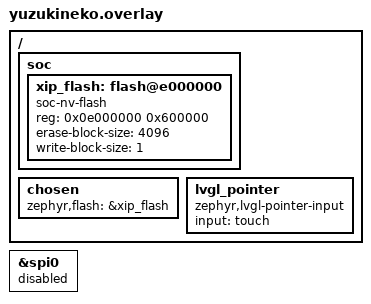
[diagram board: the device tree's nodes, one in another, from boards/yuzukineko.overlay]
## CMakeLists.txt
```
# SPDX-License-Identifier: Apache-2.0

cmake_minimum_required(VERSION 3.20.0)
# the WiFi driver sits next to this application
list(APPEND ZEPHYR_EXTRA_MODULES ${CMAKE_CURRENT_SOURCE_DIR}/../aic8800)

find_package(Zephyr REQUIRED HINTS $ENV{ZEPHYR_BASE})
project(bilibili_tv)

# math.h for the TrueType rasteriser of LVGL (the minimal C library has none); the functions are in libm
zephyr_include_directories(shim)
zephyr_link_libraries(-lm)
target_compile_options(modules__lvgl PRIVATE -include ${CMAKE_CURRENT_SOURCE_DIR}/shim/stbtt_cfg.h)
# TinyTTF releases a kerning cache entry into the glyph cache (lv_tiny_ttf.c, ttf_get_glyph_pair_kerning_width),
# which corrupts both caches: glyphs came out overlapped and with wrong advances. Without a kerning cache
# the width is computed directly (its Kconfig symbol is a bool, it cannot be set to 0 there)
target_compile_definitions(modules__lvgl PRIVATE LV_TINY_TTF_CACHE_KERNING_CNT=0)

# sources include each other by their path below src ("net/http.h")
target_include_directories(app PRIVATE src)
# LVGL includes lv_rvv.h from its blend sources
zephyr_include_directories(src/gfx)

# the video player (MP4 demultiplexer, H.264 and AAC decoders, display and sound) is a copy of the one of
# the NekoBox application, changed for a file that grows while it is played
file(GLOB PLAYER_SRC src/player/*.c)
target_sources(app PRIVATE ${PLAYER_SRC})

file(GLOB CORE_SRC src/core/*.c)
target_sources(app PRIVATE src/main.c ${CORE_SRC})
# network and file transfer, the Bilibili interface, the screens
file(GLOB NET_SRC src/net/*.c)
file(GLOB API_SRC src/api/*.c)
file(GLOB UI_SRC src/ui/*.c)
target_sources(app PRIVATE ${NET_SRC} ${API_SRC} ${UI_SRC})
target_sources_ifdef(CONFIG_BILI_SELFTEST app PRIVATE src/debug/selftest.c)
if(CONFIG_BILI_SELFTEST OR CONFIG_BILI_SCROLL_LOG)
  target_sources(app PRIVATE src/debug/profile.c)
endif()

# the Chinese font (tools/make_font.py) is part of the image
generate_inc_file_for_target(app src/ui/fonts/NotoSansSC-subset.ttf ${CMAKE_CURRENT_BINARY_DIR}/font.inc)
target_include_directories(app PRIVATE ${CMAKE_CURRENT_BINARY_DIR})

if(CONFIG_BILI_HOT_RAM)
  # only the files that run for every picture; relocating a whole library keeps every function
  set(V ${ZEPHYR_BASE}/drivers/vdec/sunxi)
  zephyr_code_relocate(FILES
    ${V}/vdec_sunxi.c ${V}/ve_hw.c ${V}/ve_mem.c ${V}/ve_pool.c ${V}/ve_session.c ${V}/ve_stream.c
    ${V}/ve_h264.c ${V}/ve_h264_parse.c ${V}/ve_h264_dpb.c ${V}/ve_h264_hw.c
    LOCATION RAM_TEXT)
  zephyr_code_relocate(LIBRARY opencore_aac LOCATION RAM_TEXT)
endif()

if(CONFIG_BILI_UI_RAM)
  # code of the interface runs from RAM: the flash window is not cached for data and every I-cache
  # miss of the drawing loops costs a flash read, which shows when the lists scroll
  zephyr_code_relocate(LIBRARY modules__lvgl LOCATION RAM_TEXT)
  zephyr_code_relocate(FILES ${UI_SRC} LOCATION RAM_TEXT)
endif()

target_sources_ifdef(CONFIG_BILI_CRUMBS app PRIVATE src/debug/crumbs.c)

if(CONFIG_BILI_GFX_RVV)
  target_sources(app PRIVATE src/gfx/lv_rvv.c)
  # only these files use vector instructions; the rest of the image is built as usual
  set_source_files_properties(src/gfx/lv_rvv.c PROPERTIES COMPILE_OPTIONS
    "-march=rv32imafdcv_zicsr_zifencei_xtheadcmo_xtheadba_xtheadbb_xtheadbs_xtheadcondmov_xtheadmemidx_xtheadmempair")
  if(CONFIG_BILI_HOT_RAM)
    zephyr_code_relocate(FILES ${CMAKE_CURRENT_SOURCE_DIR}/src/gfx/lv_rvv.c LOCATION RAM_TEXT)
  endif()
endif()

target_sources_ifdef(CONFIG_BILI_G2D_BENCH app PRIVATE src/debug/g2dbench.c)

target_sources_ifdef(CONFIG_BILI_SCROLL_SHIFT app PRIVATE src/gfx/shift.c)
```

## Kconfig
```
# SPDX-License-Identifier: Apache-2.0

mainmenu "Bilibili TV"

config BILI_WIFI_SSID
	string "Wi-Fi network to join at start"
	default ""

config BILI_WIFI_PSK
	string "Wi-Fi passphrase (empty: open network)"
	default ""

config BILI_PROXY
	string "HTTP proxy (host:port) for every request, empty for a direct connection"
	default ""
	help
	  With a proxy the plain requests are sent with the full address and the https ones through a
	  CONNECT tunnel, on which the TLS handshake is done by the application (the certificate of the
	  server is not checked). It can be changed at run time with  bili proxy <host:port|off>.

config BILI_FEED_COUNT
	int "Videos asked from the recommendation feed"
	default 12
	range 1 30

config BILI_CACHE_DIR
	string "Directory on the card where videos are stored while they play"
	default "/SD:/bilibili"

config NEKOBOX_VIDEO_STREAM_KB
	int "Stream buffer of the video decoder in KiB"
	default 256
	help
	  The videos here are 360P at under 1 Mbit/s: a quarter of a MiB holds seconds of them, and the
	  memory that the player of NekoBox would keep for 1 MiB goes to the decoder's pictures.

config BILI_HOT_RAM
	bool "Run the video decoder driver and the AAC decoder from RAM"
	default y
	depends on XIP
	select CODE_DATA_RELOCATION
	help
	  In an XIP image every instruction that is not in the cache comes from the flash window.
	  The decoder driver and the AAC decoder run on every picture, so their text is copied to RAM
	  at boot; the rest (kernel, other drivers, LVGL, the file system) stays in the flash.

config BILI_DM_MAX_ITEMS
	int "Most comments (danmaku) kept of a video"
	default 4000
	range 100 20000

config BILI_DM_POOL_KB
	int "Memory for the text of the comments (KiB)"
	default 160
	range 16 2048

config BILI_DM_ACTIVE
	int "Comments on the screen at the same time"
	default 20
	range 4 60
	help
	  Each one is a label that LVGL has to redraw while it moves: this is what the player pays for the
	  comments. A comment that finds no free label or lane within a second and a half is dropped.

config BILI_STREAM
	bool "Play while the file downloads"
	default y
	help
	  Off: the whole file is downloaded first (a long wait for a big video).

config BILI_UI_RAM
	bool "Run LVGL and the interface code from RAM"
	depends on XIP
	select CODE_DATA_RELOCATION
	default y

config BILI_PREBUFFER_SEC
	int "Seconds of video to download before playing starts"
	default 6
	range 0 30
	help
	  Avoids stalls in the first seconds while the connection speeds up. 0: start at once.

config BILI_PREBUFFER_TIMEOUT_SEC
	int "Longest wait for the prebuffer, in seconds"
	default 20
	range 1 120

config BILI_DM_FETCH
	bool "Fetch the comments of a video before it plays"
	default y

config BILI_DM_SHIFT
	bool "Move the picture of the scrolling comments with the 2D accelerator"
	default y
	help
	  The scrolling comments all move with the same speed. The picture of their lanes is moved to
	  the left by the accelerator and only the columns that come in at the right are drawn, instead of
	  drawing every label again at its new place.

config BILI_DM_VSYNC
	bool "Wait for the vertical blank before the scrolling comments are moved"
	depends on BILI_DM_SHIFT
	default n
	help
	  Without the wait the interface does not stand still for about 11 ms per round; the move of a
	  few pixels may show a seam for one frame.

config BILI_DM_DEFAULT
	bool "Show the comments when a video starts"
	default y

config BILI_SELFTEST
	bool "Scroll the list, search, play videos and check the memory by itself, ending with PASS or FAIL"
	select THREAD_MONITOR
	select THREAD_NAME
	select THREAD_RUNTIME_STATS
	select SYS_HEAP_RUNTIME_STATS
	help
	  Needs the network and the card. See src/debug/selftest.c.

config BILI_SELFTEST_ROUNDS
	int "Times the list is scrolled to its end and back"
	depends on BILI_SELFTEST
	default 3

config BILI_SELFTEST_PLAYS
	int "Videos that are played"
	depends on BILI_SELFTEST
	default 3

config BILI_HEARTBEAT
	bool "Print a line with the state of the cover cache every 10 s"
	default y

config BILI_COVER_THREADS
	int "Threads that fetch cover pictures at the same time"
	default 3
	range 1 6

config BILI_COVER_CACHE
	int "Cover pictures kept in memory (62 KiB each)"
	default 24
	range 8 60

config BILI_CDN_HTTPS
	bool "Fetch the video over TLS too"
	default y
	help
	  Every connection to a Bilibili server is encrypted: the API always, the video with this option
	  (an address that comes as http:// is changed to https://). The video servers also answer on
	  plain HTTP, which costs the CPU nothing.

config BILI_COVER_HTTPS
	bool "Fetch the covers and the pictures of the users over TLS"
	default y
	help
	  The picture servers also answer on plain HTTP. With TLS every picture costs a handshake.

config BILI_TLS_VERIFY
	bool "Check the certificate of the API server"
	help
	  Needs the root certificate to be registered (not done yet): with this off the connection is
	  encrypted but the server is not authenticated.

source "Kconfig.zephyr"

config BILI_CPU_MHZ
	int "CPU clock in MHz, 0 keeps what the boot stub set up (600)"
	default 600
	help
	  The CPU PLL is raised in steps of 72 MHz and the memory is checked after each step. The
	  voltage is not changed.

config BILI_CRUMBS
	bool "Keep the last context switches in memory and reset by a watchdog when the system stops"
	default y
	select WATCHDOG
	select WDT_SUNXI
	select THREAD_NAME

config BILI_CRUMBS_TIMEOUT_MS
	int "Watchdog time out in ms"
	depends on BILI_CRUMBS
	default 8000

config BILI_CRUMBS_TEST_S
	int "Stop the system after this many seconds (0: never), to try the recorder"
	depends on BILI_CRUMBS
	default 0

config BILI_SELFTEST_PLAY_POPULAR
	bool "Play the videos of the popular list (default: the recommended ones)"
	depends on BILI_SELFTEST

config BILI_SELFTEST_PLAY_SECONDS
	int "Seconds each video is played"
	depends on BILI_SELFTEST
	default 12
	range 12 600

config BILI_DM_LOG
	bool "Print how long the interface rounds take while comments are shown"
	default n

config BILI_SELFTEST_WIFI_ONLY
	bool "Only try the connection (leave, join again, wrong password, forget and save again)"
	depends on BILI_SELFTEST

config BILI_SELFTEST_PLAY_ONLY
	bool "Self test: load the list and play videos one after another, nothing else"
	depends on BILI_SELFTEST
	default n

config BILI_GFX_RVV
	bool "Vector code for the blends of LVGL"
	default y
	select SUN252I_F101_RVV
	help
	  The blends are compared with the C code of LVGL at start and the vector code is switched off
	  when they differ.

config BILI_G2D_BENCH
	bool "Measure the 2D accelerator against the processor at start"
	select G2D
	select G2D_SUNXI
	default n

config BILI_SCROLL_LOG
	bool "Print the refreshes that take longer than 40 ms"
	select THREAD_MONITOR
	select THREAD_NAME
	select THREAD_RUNTIME_STATS
	default n

config BILI_SCROLL_SHIFT
	bool "Scroll a list by moving the picture with the 2D accelerator and drawing only the new rows"
	select G2D
	select G2D_SUNXI
	default y

config BILI_COVER_G2D
	bool "Convert the pictures of the covers with the 2D accelerator"
	select G2D
	select G2D_SUNXI
	default y
```

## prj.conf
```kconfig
# the whole image runs in place from the flash window of the SPIF controller (boards/yuzukineko.overlay)
CONFIG_XIP=y

CONFIG_SDHC=y
CONFIG_DISK_ACCESS=y
CONFIG_DISK_DRIVER_SDMMC=y
CONFIG_FILE_SYSTEM=y
CONFIG_FAT_FILESYSTEM_ELM=y
CONFIG_FS_FATFS_EXFAT=y
CONFIG_FS_FATFS_LFN=y
CONFIG_FS_FATFS_LFN_MODE_STACK=y
# the audio and the video thread read the same card, and the downloader writes to it
CONFIG_FS_FATFS_REENTRANT=y
CONFIG_FS_FATFS_MKFS=n
CONFIG_FS_FATFS_MOUNT_MKFS=n

CONFIG_LOG=y
CONFIG_LOG_PRINTK=n
CONFIG_PRINTK=y
CONFIG_SHELL=n
# stack use of every thread: kernel stacks; an overflow is caught by the sentinel
CONFIG_THREAD_STACK_INFO=y
CONFIG_INIT_STACKS=y
CONFIG_STACK_SENTINEL=y
CONFIG_DEVMEM_SHELL=n
CONFIG_MAIN_STACK_SIZE=16384
CONFIG_COMMON_LIBC_MALLOC_ARENA_SIZE=-1
CONFIG_HEAP_MEM_POOL_SIZE=131072
CONFIG_MAIN_THREAD_PRIORITY=6
CONFIG_THREAD_NAME=y
CONFIG_SPEED_OPTIMIZATIONS=y

# drivers the application does not use
# CONFIG_G2D is selected by BILI_G2D_BENCH
CONFIG_ADC=n
CONFIG_SPI=n
CONFIG_MIPI_DBI=n
CONFIG_WDT_SUNXI=y
CONFIG_GPIO=y
CONFIG_FPU=y
CONFIG_FPU_SHARING=y

# the player. The budget of the video decoder is what is left of the 16 MB after the image (the font, the
# frame buffer and the WiFi firmware are in it): the stream buffer (NEKOBOX_VIDEO_STREAM_KB, 256) and the
# rest for the pictures, 4300 KiB is 11 pictures of 640x360. With 3200 only 6 were made, the decoder
# (references, the picture in work, the converted one, the one on the screen) found none free and stood
# still after the first picture; with 9 there were pictures late all the time. 12288, the default, does
# not fit the memory.
CONFIG_VDEC_SUNXI_MAX_MEMORY_KB=8192
CONFIG_MP4_DEMUX=y
CONFIG_VDEC=y
CONFIG_I2S=y
CONFIG_AUDIO=y
CONFIG_AUDIO_CODEC=y
CONFIG_DMA=y
CONFIG_OPENCORE_AAC=y

# the user interface: LVGL on the ARGB frame buffer plane, over the video plane
CONFIG_DISPLAY=y
CONFIG_DISPLAY_SUNXI_ARGB8888=y
CONFIG_LVGL=y
CONFIG_LV_COLOR_DEPTH_32=y
CONFIG_LV_Z_MEM_POOL_SIZE=720896
CONFIG_LV_Z_VDB_SIZE=10
CONFIG_LV_Z_SHELL=n
CONFIG_LV_USE_LABEL=y
CONFIG_LV_USE_BUTTON=y
CONFIG_LV_USE_BAR=y
# bili shot: the screen as a picture over the serial line (there is no camera on the bench)
CONFIG_LV_USE_SNAPSHOT=y
# a character that the font does not have is left blank, not drawn as a box
CONFIG_LV_USE_FONT_PLACEHOLDER=n
CONFIG_LV_USE_KEYBOARD=y
CONFIG_LV_USE_TEXTAREA=y
CONFIG_LV_USE_QRCODE=y
CONFIG_LV_USE_IME_PINYIN=y
CONFIG_LV_IME_PINYIN_USE_DEFAULT_DICT=n
CONFIG_LV_IME_PINYIN_CAND_TEXT_NUM=10
CONFIG_LV_FONT_MONTSERRAT_16=y
CONFIG_LV_FONT_MONTSERRAT_20=y
CONFIG_LV_FONT_MONTSERRAT_28=y
# the Chinese font is in the image
CONFIG_LV_USE_TINY_TTF=y
# software JPEG decoder for the covers that the video engine refuses
CONFIG_LV_USE_TJPGD=y

# Wi-Fi (AIC8800 on SMHC2)
CONFIG_AIC8800=y
# the driver used at most 310 KiB of its pool in the tests
CONFIG_AIC8800_MEM_POOL_KB=640
CONFIG_TEST_RANDOM_GENERATOR=y
CONFIG_SYSTEM_WORKQUEUE_STACK_SIZE=4096
CONFIG_NET_MGMT_EVENT_STACK_SIZE=3072
CONFIG_NET_RX_STACK_SIZE=3072
CONFIG_NET_TX_STACK_SIZE=2048
CONFIG_NET_TCP_WORKQ_STACK_SIZE=3072
CONFIG_NET_IPV6=n
CONFIG_NET_UDP=y
CONFIG_NET_TCP=y
CONFIG_NET_DHCPV4=y
CONFIG_NET_DHCPV4_OPTION_DNS_ADDRESS=y
CONFIG_NET_SOCKETS=y
# the receive window must fit in the buffers: a burst of a peer with a bigger window than the pool was
# dropped and every loss cost a retransmission time out (a 10 KB cover took 2 s)
CONFIG_NET_BUF_DATA_SIZE=512
CONFIG_NET_BUF_RX_COUNT=192
CONFIG_NET_BUF_TX_COUNT=96
CONFIG_NET_PKT_RX_COUNT=64
CONFIG_NET_PKT_TX_COUNT=48
CONFIG_NET_TCP_MAX_RECV_WINDOW_SIZE=16384
# every request opens a connection of its own; a closed one is held for the time wait: with the cover
# threads the table of 16 ran out ("Not enough connection contexts", connect() answered ENOENT)
CONFIG_NET_MAX_CONN=48
CONFIG_NET_MAX_CONTEXTS=48
CONFIG_NET_TCP_TIME_WAIT_DELAY=500
CONFIG_NET_CONTEXT_RCVTIMEO=y
CONFIG_NET_CONTEXT_SNDTIMEO=y
CONFIG_DNS_RESOLVER=y
CONFIG_DNS_RESOLVER_MAX_SERVERS=2
# the answer of api.bilibili.com has six addresses; a longer answer than this makes getaddrinfo() fail
CONFIG_DNS_RESOLVER_AI_MAX_ENTRIES=8
# the cover threads, the worker and the downloads resolve names at the same time; the default is one query at a time and the others get EAGAIN
CONFIG_DNS_NUM_CONCUR_QUERIES=6

# TLS for the API (the answers are a few KiB, but a handshake needs the records of the server)
CONFIG_NET_SOCKETS_SOCKOPT_TLS=y
CONFIG_MBEDTLS=y
CONFIG_MBEDTLS_BUILTIN=y
CONFIG_MBEDTLS_ENABLE_HEAP=y
# every connection to a Bilibili server is encrypted: the cover threads, the worker and the download
# can each have one open at the same time (about 55 KiB of the mbed TLS heap each)
CONFIG_NET_SOCKETS_TLS_MAX_CONTEXTS=4
CONFIG_MBEDTLS_HEAP_SIZE=262144
CONFIG_MBEDTLS_SSL_IN_CONTENT_LEN=16384
CONFIG_MBEDTLS_SSL_OUT_CONTENT_LEN=16384
CONFIG_PSA_CRYPTO=y
CONFIG_MBEDTLS_SSL_PROTO_TLS1_2=y
CONFIG_MBEDTLS_SSL_SERVER_NAME_INDICATION=y
CONFIG_MBEDTLS_X509_CRT_PARSE_C=y
CONFIG_PSA_WANT_ALG_ECDH=y
CONFIG_PSA_WANT_KEY_TYPE_ECC_KEY_PAIR_GENERATE=y
CONFIG_PSA_WANT_KEY_TYPE_ECC_KEY_PAIR_IMPORT=y
CONFIG_PSA_WANT_KEY_TYPE_RSA_KEY_PAIR_IMPORT=y
CONFIG_PSA_WANT_KEY_TYPE_RSA_PUBLIC_KEY=y
CONFIG_PSA_WANT_ALG_RSA_PKCS1V15_SIGN=y
CONFIG_PSA_WANT_ALG_RSA_PSS=y
CONFIG_PSA_WANT_ALG_RSA_OAEP=y
CONFIG_PSA_WANT_ECC_SECP_R1_256=y
CONFIG_PSA_WANT_ECC_MONTGOMERY_255=y
CONFIG_PSA_WANT_KEY_TYPE_AES=y
CONFIG_PSA_WANT_ALG_GCM=y
CONFIG_MBEDTLS_KEY_EXCHANGE_ECDHE_RSA_ENABLED=y
CONFIG_MBEDTLS_HASH_ALL_ENABLED=y

# a player that queues shown pictures needs spare ones (a torn picture when the conversion finds none)
CONFIG_VDEC_SUNXI_H264_EXTRA_PICTURES=8



# BILI_CRUMBS needs the user tracing hooks
CONFIG_TRACING=y
CONFIG_TRACING_USER=y

# the vector blends of the software renderer (BILI_GFX_RVV)
CONFIG_LV_DRAW_SW_ASM_CUSTOM=y
CONFIG_LV_DRAW_SW_ASM_CUSTOM_INCLUDE="lv_rvv.h"
```

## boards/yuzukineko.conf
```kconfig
# the touch panel: the controller is on I2C, the input thread runs above the UI and the player
CONFIG_I2C=y
CONFIG_INPUT=y
CONFIG_INPUT_GT967_MAX_TOUCH_POINTS=2
CONFIG_INPUT_THREAD_PRIORITY_OVERRIDE=y
CONFIG_INPUT_THREAD_PRIORITY=2
CONFIG_INPUT_QUEUE_MAX_MSGS=64
CONFIG_LV_Z_POINTER_INPUT_MSGQ_COUNT=32
```

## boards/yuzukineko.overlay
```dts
/*
 * The image runs in place from the flash: it is linked into the window of the SPIF controller, which
 * the boot stub (SyterKit xip-boot) maps from the flash offset 0x80000 at 0x0e000000. The window is
 * 6 MiB, the same as the stub's.
 */
/ {
	soc {
		xip_flash: flash@e000000 {
			compatible = "soc-nv-flash";
			reg = <0x0e000000 0x600000>;
			erase-block-size = <4096>;
			write-block-size = <1>;
		};
	};

	chosen {
		zephyr,flash = &xip_flash;
	};

	/* LVGL reads the touch panel as a pointer: the list can be tapped */
	lvgl_pointer {
		compatible = "zephyr,lvgl-pointer-input";
		input = <&touch>;
	};
};

/* spi0 uses the pins of the flash (PC0..PC5): switching them away would cut the window off */
&spi0 {
	status = "disabled";
};
```

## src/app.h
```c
/*
 * Copyright (c) 2026 Yuzuki Tsuru
 *
 * SPDX-License-Identifier: Apache-2.0
 */

#ifndef BILI_APP_H_
#define BILI_APP_H_

#include <stdbool.h>
#include <stdint.h>

#include "bili_parse.h"
#include "danmaku.h"

#define MAX_VIDEOS	100

enum list_id {
	LIST_RECOMMEND,
	LIST_POPULAR,
	LIST_SEARCH,
	LIST_COUNT,
};

enum app_cmd_type {
	CMD_REFRESH,	/**< arg: list, load its first page again */
	CMD_MORE,	/**< arg: list, append the next page */
	CMD_SEARCH,	/**< keyword in the command: a new search */
	CMD_HOT,	/**< fetch the trending search words */
	CMD_PLAY,	/**< arg: list << 16 | index */
	CMD_STOP,	/**< back from the player */
	CMD_PAUSE,	/**< toggles */
	CMD_WIFI,	/**< join the network in ssid / psk */
};

/** Posts a command to the worker thread; may be called from any thread */
void app_cmd(enum app_cmd_type type, int arg);
void app_cmd_wifi(const char *ssid, const char *psk);
void app_cmd_search(const char *keyword);

/** What a list holds now; @p gen changes when the list was replaced (a refresh or a new search) */
struct list_info {
	int count;
	uint32_t gen;
	bool more;	/**< another page may exist */
	bool loading;	/**< the worker is fetching a page */
	int error;	/**< the last page request failed with this (0: it worked) */
};
void app_list_info(enum list_id list, struct list_info *info);

/** What malloc can still give: blocks of 64 KiB (all, in KiB) and the biggest single block (KiB) */
void app_mem_probe(unsigned int *free_kib, unsigned int *biggest_kib);

/** Copy of a video of a list, false when there is none */
bool app_video(enum list_id list, int index, struct bili_video *out);

/* ---- the user interface; the setters may be called from any thread ----------------------- */

void ui_init(void);
/** Runs in the thread that owns LVGL: applies what the setters stored and draws; returns the ms to the next call */
uint32_t ui_run(void);

/** For the self test: type keys on the search keyboard, pick a candidate (-1: none), press search */
void ui_type(const char *keys, int pick, bool submit_now);

/** Shows the home (0) or the search (1) page; for the self test */
void ui_goto(int page);

void ui_set_status(const char *fmt, ...) __attribute__((format(printf, 1, 2)));
void ui_set_hot_words(char words[][BILI_HOT_WORD_LEN], int count);
/** The comments of the video that is about to play; the UI takes the set over (NULL: none) */
void ui_set_danmaku(struct dm_set *set);

/** @p title NULL leaves the player screen */
void ui_set_playing(const char *title, uint32_t duration_ms);
void ui_set_position(uint32_t pos_ms, bool paused);
/** How much of the video is in the file (0..1000), for the progress bar of the player page */
void ui_set_buffered(int permille);

/** For the self test: scrolls the list of the home page by @p dy pixels; false at the end */
bool ui_home_scroll(int dy);
/** For the self test: selects the tab of the home page (0 recommend, 1 popular) */
void ui_home_tab(int tab);
/** For the self test: the page that is shown (0 home, 1 search, 2 player) */
int ui_current_page(void);

#endif /* BILI_APP_H_ */
```

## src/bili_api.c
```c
/*
 * Copyright (c) 2026 Yuzuki Tsuru
 *
 * SPDX-License-Identifier: Apache-2.0
 */

#include <errno.h>
#include <stdio.h>
#include <stdlib.h>
#include <string.h>
#include <zephyr/kernel.h>
#include <zephyr/sys/printk.h>

#include "bili_api.h"
#include "http.h"
#include "inflate.h"
#include "json.h"
#include "wbi.h"

#define API		"https://api.bilibili.com"
#define ANSWER_MAX	(128 * 1024)
#define QN_360P		16

#define CODE_RISK	(-412)	/* too many requests / no browser identity */
#define CODE_SIGN_1	(-403)	/* the signature or its key is wrong */
#define CODE_SIGN_2	(-352)

static char wbi_key[33];
/* "Cookie: buvid3=...; buvid4=...\r\n" once the server has asked for a browser identity */
static char cookie_hdr[256];

/*
 * The server does not check the time stamp of a signed request, so the clock of the board, which
 * has no network time, does not have to be right.
 */
static int64_t stamp(void)
{
	return 1700000000 + k_uptime_get() / 1000;
}

/* one request: the whole answer in a new buffer, NULL when the transfer failed */
static char *fetch(const char *url)
{
	struct http_opts o = {
		.range_start = -1,
		.tls_verify = IS_ENABLED(CONFIG_BILI_TLS_VERIFY),
		.headers = cookie_hdr[0] != '\0' ? cookie_hdr : NULL,
	};
	char *buf = malloc(ANSWER_MAX);
	int n;

	if (buf == NULL) {
		return NULL;
	}
	n = http_get_text(url, &o, buf, ANSWER_MAX, NULL);
	if (n < 0) {
		printk("api: %s failed (%d)\n", url + sizeof(API) - 1, n);
		free(buf);
		return NULL;
	}

	return buf;
}

/* the signing key comes with the nav answer, which needs no login (the answer is code -101) */
static int load_key(void)
{
	char *a = fetch(API "/x/web-interface/nav");
	int ret;

	if (a == NULL) {
		return -EIO;
	}
	ret = bili_parse_nav(a, wbi_key);
	free(a);
	if (ret != 0) {
		printk("api: no signing key in the nav answer\n");
	}

	return ret;
}

/* the browser identity: two random looking ids that the search wants as cookies */
static int load_cookie(void)
{
	char *a = fetch(API "/x/frontend/finger/spi");
	char b3[80], b4[96];
	int ret = -EBADMSG;

	if (a == NULL) {
		return -EIO;
	}
	if (js_str(js_path(a, "data.b_3"), b3, sizeof(b3)) > 0 &&
	    js_str(js_path(a, "data.b_4"), b4, sizeof(b4)) > 0) {
		snprintf(cookie_hdr, sizeof(cookie_hdr), "Cookie: buvid3=%s; buvid4=%s\r\n", b3, b4);
		ret = 0;
	}
	free(a);

	return ret;
}

/*
 * A signed call. Returns the answer with code 0, or NULL (the code is in *code, 0 when there was
 * no answer). A refused signature gets a new key and a risk answer gets the cookie, once each.
 */
static char *call(const char *path, const char *const *params, int count, int *code)
{
	bool new_key = false, new_cookie = false;

	for (;;) {
		char url[800], query[600], *a;
		int ret;

		*code = 0;
		if (wbi_key[0] == '\0' && load_key() != 0) {
			return NULL;
		}
		ret = wbi_query(params, count, wbi_key, stamp(), query, sizeof(query));
		if (ret < 0) {
			return NULL;
		}
		snprintf(url, sizeof(url), API "%s?%s", path, query);
		a = fetch(url);
		if (a == NULL) {
			return NULL;
		}
		*code = bili_parse_code(a);
		if (*code == 0) {
			return a;
		}
		free(a);
		printk("api: %s answered code %d\n", path, *code);
		if ((*code == CODE_SIGN_1 || *code == CODE_SIGN_2) && !new_key) {
			new_key = true;
			wbi_key[0] = '\0';
		} else if (*code == CODE_RISK && !new_cookie) {
			new_cookie = true;
			if (load_cookie() != 0) {
				return NULL;
			}
		} else {
			return NULL;
		}
	}
}

int bili_api_feed(int page, struct bili_video *out, int max)
{
	char ps[16], idx[24];
	const char *params[] = {ps, "fresh_type=4", idx, "web_location=1430650"};
	char *a;
	int n, code;

	snprintf(ps, sizeof(ps), "ps=%d", max);
	snprintf(idx, sizeof(idx), "fresh_idx=%d", page);
	a = call("/x/web-interface/wbi/index/top/feed/rcmd", params, ARRAY_SIZE(params), &code);
	if (a == NULL) {
		return code != 0 ? -EACCES : -EIO;
	}
	n = bili_parse_feed(a, out, max);
	free(a);

	return n;
}

int bili_api_popular(int page, struct bili_video *out, int max)
{
	char ps[16], pn[16];
	const char *params[] = {ps, pn};
	char *a;
	int n, code;

	snprintf(ps, sizeof(ps), "ps=%d", max);
	snprintf(pn, sizeof(pn), "pn=%d", page);
	a = call("/x/web-interface/popular", params, ARRAY_SIZE(params), &code);
	if (a == NULL) {
		return code != 0 ? -EACCES : -EIO;
	}
	n = bili_parse_popular(a, out, max);
	free(a);

	return n;
}

int bili_api_search(const char *keyword, int page, struct bili_video *out, int max, int *pages)
{
	char kw[128], pg[16];
	const char *params[] = {"search_type=video", kw, pg};
	char *a;
	int n, code;

	snprintf(kw, sizeof(kw), "keyword=%s", keyword);
	snprintf(pg, sizeof(pg), "page=%d", page);
	a = call("/x/web-interface/wbi/search/type", params, ARRAY_SIZE(params), &code);
	if (a == NULL) {
		return code != 0 ? -EACCES : -EIO;
	}
	n = bili_parse_search(a, out, max, pages);
	free(a);

	return n;
}

int bili_api_hot_words(char words[][BILI_HOT_WORD_LEN], int max)
{
	const char *params[] = {"limit=10"};
	char *a;
	int n, code;

	a = call("/x/web-interface/wbi/search/square", params, ARRAY_SIZE(params), &code);
	if (a == NULL) {
		return code != 0 ? -EACCES : -EIO;
	}
	n = bili_parse_hot_words(a, words, max);
	free(a);

	return n;
}

/* the cid of a video that came without one */
static int resolve_cid(const char *bvid, uint64_t *cid)
{
	char b[32];
	const char *params[] = {b};
	char *a;
	int ret, code;

	snprintf(b, sizeof(b), "bvid=%s", bvid);
	a = call("/x/player/pagelist", params, ARRAY_SIZE(params), &code);
	if (a == NULL) {
		return code != 0 ? -EACCES : -EIO;
	}
	ret = bili_parse_view_cid(a, cid);
	free(a);

	return ret;
}

int bili_api_stream(const struct bili_video *v, struct bili_stream *out)
{
	char bvid[32], cid[32], qn[16];
	const char *params[] = {bvid, cid, qn, "fnval=0", "fnver=0", "fourk=0", "platform=html5",
				"high_quality=1"};
	uint64_t id = v->cid;
	char *a;
	int ret, code;

	if (id == 0) {
		ret = resolve_cid(v->bvid, &id);
		if (ret != 0) {
			return ret;
		}
	}
	snprintf(bvid, sizeof(bvid), "bvid=%s", v->bvid);
	snprintf(cid, sizeof(cid), "cid=%llu", (unsigned long long)id);
	snprintf(qn, sizeof(qn), "qn=%d", QN_360P);
	a = call("/x/player/wbi/playurl", params, ARRAY_SIZE(params), &code);
	if (a == NULL) {
		return code != 0 ? -EACCES : -EIO;
	}
	ret = bili_parse_playurl(a, out);
	out->cid = id;
	free(a);
	if (ret == 0 && !IS_ENABLED(CONFIG_BILI_CDN_HTTPS) && strncmp(out->url, "https://", 8) == 0) {
		/* the video servers answer on port 80 as well, without the cost of the encryption */
		memmove(out->url + 4, out->url + 5, strlen(out->url + 5) + 1);
	}

	return ret;
}

/* ---- the comments -------------------------------------------------------------------------- */

struct dm_sink {
	struct inflate *inf;
	struct dm_parser *parser;
	bool started, plain;
	int status;
};

/* decoded bytes of the XML */
static int dm_xml(void *ctx, const uint8_t *d, size_t n)
{
	return dm_parser_feed(ctx, d, n);
}

/* the bytes of the answer: raw deflate as the server sends it, or the XML itself */
static int dm_body(void *ctx, const uint8_t *d, size_t n)
{
	struct dm_sink *s = ctx;
	int ret;

	if (!s->started) {
		s->started = true;
		s->plain = n > 0 && d[0] == '<';
	}
	if (s->plain) {
		return dm_parser_feed(s->parser, d, n);
	}
	ret = inflate_feed(s->inf, d, n);

	return ret < 0 ? ret : 0;	/* 1: the stream is complete, what follows is of no interest */
}

int bili_api_danmaku(uint64_t cid, struct dm_set *set)
{
	char url[96];
	struct dm_sink sink = {0};
	struct http_result r;
	struct http_opts o = {.range_start = -1, .tls_verify = IS_ENABLED(CONFIG_BILI_TLS_VERIFY), .timeout_ms = 15000,
			      .headers = cookie_hdr[0] != '\0' ? cookie_hdr : NULL};
	int ret;

	snprintf(url, sizeof(url), API "/x/v1/dm/list.so?oid=%llu", (unsigned long long)cid);
	sink.parser = dm_parser_new(set);
	sink.inf = inflate_new(dm_xml, sink.parser);
	if (sink.parser == NULL || sink.inf == NULL) {
		ret = -ENOMEM;
		goto out;
	}
	ret = http_get(url, &o, dm_body, &sink, &r);
	if (ret == 0 && r.status / 100 != 2) {
		ret = -EIO;
	}
	if (ret != 0) {
		printk("api: danmaku of %llu failed (%d), %u read\n", (unsigned long long)cid, ret, set->count);
	}
out:
	if (sink.parser != NULL) {
		dm_parser_finish(sink.parser);
	}
	dm_parser_free(sink.parser);
	inflate_free(sink.inf);

	return set->count > 0 || ret == 0 ? (int)set->count : ret;
}
```

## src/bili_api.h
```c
/*
 * Copyright (c) 2026 Yuzuki Tsuru
 *
 * SPDX-License-Identifier: Apache-2.0
 */

#ifndef BILI_API_H_
#define BILI_API_H_

#include "bili_parse.h"
#include "danmaku.h"

/*
 * All calls block, talk to the server and are meant for one thread (the worker): the signing key
 * and the cookie they keep are not protected. They return the number of items (or 0 for success)
 * or a negative errno.
 */

/** A page of the recommendation feed (page counts from 1) */
int bili_api_feed(int page, struct bili_video *out, int max);

/** A page of the popular list (page counts from 1) */
int bili_api_popular(int page, struct bili_video *out, int max);

/** A page of the results for a keyword (UTF-8); @p pages gets the number of pages */
int bili_api_search(const char *keyword, int page, struct bili_video *out, int max, int *pages);

/** The trending search words */
int bili_api_hot_words(char words[][BILI_HOT_WORD_LEN], int max);

/** The 360P file of a video; a video without cid (a search result) is looked up first */
int bili_api_stream(const struct bili_video *v, struct bili_stream *out);

/**
 * The comments of a video (no login needed): fetched, inflated and read into @p set (which the caller
 * has set up with dm_init() and frees). Returns the number of comments, or a negative errno; a broken
 * transfer keeps what was read until then.
 */
int bili_api_danmaku(uint64_t cid, struct dm_set *set);

#endif /* BILI_API_H_ */
```

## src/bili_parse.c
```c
/*
 * Copyright (c) 2026 Yuzuki Tsuru
 *
 * SPDX-License-Identifier: Apache-2.0
 */

#include <errno.h>
#include <stdio.h>
#include <stdlib.h>
#include <string.h>

#include "bili_parse.h"
#include "json.h"
#include "wbi.h"

int bili_parse_code(const char *json)
{
	const char *c = js_get(json, "code");

	if (c == NULL) {
		return -EBADMSG;
	}

	return (int)js_int(c, -EBADMSG);
}

int bili_parse_nav(const char *json, char key[33])
{
	char img[128], sub[128];
	const char *w = js_path(json, "data.wbi_img");

	if (js_str(js_get(w, "img_url"), img, sizeof(img)) < 0 ||
	    js_str(js_get(w, "sub_url"), sub, sizeof(sub)) < 0) {
		return -EBADMSG;
	}

	return wbi_make_key(img, sub, key);
}

/* a number that the server sometimes sends as a string ("85158") */
static long long num(const char *v, long long def)
{
	if (v != NULL && *v == '"') {
		v++;
	}

	return js_int(v, def);
}

void bili_fold_width(char *s);

static void fill_common(const char *it, struct bili_video *v)
{
	bili_fold_width(v->title);
	if (js_str(js_path(it, "owner.name"), v->author, sizeof(v->author)) < 0 &&
	    js_str(js_get(it, "author"), v->author, sizeof(v->author)) < 0) {
		v->author[0] = '\0';
	}
	bili_fold_width(v->author);
	if (js_str(js_get(it, "pic"), v->cover, sizeof(v->cover)) < 0) {
		v->cover[0] = '\0';
	}
	v->cid = num(js_get(it, "cid"), 0);
	v->views = num(js_path(it, "stat.view"), num(js_get(it, "play"), 0));
	v->danmaku = num(js_path(it, "stat.danmaku"), num(js_get(it, "danmaku"), 0));
}

static int parse_video(const char *it, struct bili_video *v)
{
	if (!js_is(js_get(it, "goto"), "av") ||
	    js_str(js_get(it, "bvid"), v->bvid, sizeof(v->bvid)) <= 0 ||
	    js_str(js_get(it, "title"), v->title, sizeof(v->title)) < 0) {
		return -EBADMSG;
	}
	fill_common(it, v);
	v->duration = js_int(js_get(it, "duration"), 0);

	return v->cid != 0 ? 0 : -EBADMSG;
}

int bili_parse_feed(const char *json, struct bili_video *out, int max)
{
	int n = 0;

	for (const char *it = js_first(js_path(json, "data.item")); it != NULL && n < max;
	     it = js_next(it)) {
		if (parse_video(it, &out[n]) == 0) {
			n++;
		}
	}

	return n;
}

int bili_parse_popular(const char *json, struct bili_video *out, int max)
{
	int n = 0;

	for (const char *it = js_first(js_path(json, "data.list")); it != NULL && n < max;
	     it = js_next(it)) {
		struct bili_video *v = &out[n];

		if (js_str(js_get(it, "bvid"), v->bvid, sizeof(v->bvid)) <= 0 ||
		    js_str(js_get(it, "title"), v->title, sizeof(v->title)) < 0) {
			continue;
		}
		fill_common(it, v);
		v->duration = js_int(js_get(it, "duration"), 0);
		if (v->cid != 0) {
			n++;
		}
	}

	return n;
}

int bili_parse_search(const char *json, struct bili_video *out, int max, int *pages)
{
	int n = 0;

	if (pages != NULL) {
		*pages = num(js_path(json, "data.numPages"), 0);
	}
	for (const char *it = js_first(js_path(json, "data.result")); it != NULL && n < max;
	     it = js_next(it)) {
		struct bili_video *v = &out[n];
		char dur[16];

		if (js_str(js_get(it, "bvid"), v->bvid, sizeof(v->bvid)) <= 0 ||
		    js_str(js_get(it, "title"), v->title, sizeof(v->title)) < 0) {
			continue;
		}
		bili_strip_html(v->title);
		fill_common(it, v);
		v->cid = 0;
		v->duration = js_str(js_get(it, "duration"), dur, sizeof(dur)) > 0 ?
			      bili_parse_clock(dur) : 0;
		n++;
	}

	return n;
}

int bili_parse_hot_words(const char *json, char words[][BILI_HOT_WORD_LEN], int max)
{
	int n = 0;

	for (const char *it = js_first(js_path(json, "data.trending.list")); it != NULL && n < max;
	     it = js_next(it)) {
		if (js_str(js_get(it, "keyword"), words[n], BILI_HOT_WORD_LEN) > 0) {
			n++;
		}
	}

	return n;
}

int bili_parse_view_cid(const char *json, uint64_t *cid)
{
	long long v = js_int(js_get(js_first(js_get(json, "data")), "cid"), 0);

	if (v == 0) {
		v = js_int(js_path(json, "data.cid"), 0);
	}
	*cid = v;

	return v != 0 ? 0 : -ENOENT;
}

/* full width Latin letters, digits and punctuation (U+FF01..FF5E) and the ideographic space become the
 * ordinary ones: the font draws them at the width of a Chinese character, which ruins the look of a title */
void bili_fold_width(char *s)
{
	char *w = s;

	while (*s != '\0') {
		if ((uint8_t)s[0] == 0xef && ((uint8_t)s[1] == 0xbc || (uint8_t)s[1] == 0xbd) &&
		    ((uint8_t)s[2] & 0xc0) == 0x80) {
			unsigned int cp = 0xff00 + ((uint8_t)s[1] == 0xbd ? 0x40 : 0) + ((uint8_t)s[2] - 0x80);

			if (cp >= 0xff01 && cp <= 0xff5e) {
				*w++ = (char)(cp - 0xff00 + 0x20);
				s += 3;
				continue;
			}
		}
		if ((uint8_t)s[0] == 0xe3 && (uint8_t)s[1] == 0x80 && (uint8_t)s[2] == 0x80) {
			*w++ = ' ';
			s += 3;
			continue;
		}
		*w++ = *s++;
	}
	*w = '\0';
}


void bili_strip_html(char *s)
{
	static const struct {
		const char *ent;
		char ch;
	} ents[] = {{"&amp;", '&'}, {"&lt;", '<'}, {"&gt;", '>'}, {"&quot;", '"'}, {"&#39;", '\''},
		    {"&apos;", '\''}};
	char *w = s;

	while (*s != '\0') {
		if (*s == '<') {
			const char *end = strchr(s, '>');

			if (end != NULL) {
				s = (char *)end + 1;
				continue;
			}
		}
		if (*s == '&') {
			size_t i;

			for (i = 0; i < sizeof(ents) / sizeof(ents[0]); i++) {
				size_t l = strlen(ents[i].ent);

				if (strncmp(s, ents[i].ent, l) == 0) {
					*w++ = ents[i].ch;
					s += l;
					break;
				}
			}
			if (i < sizeof(ents) / sizeof(ents[0])) {
				continue;
			}
		}
		*w++ = *s++;
	}
	*w = '\0';
}

uint32_t bili_parse_clock(const char *s)
{
	uint32_t total = 0, cur = 0;
	int digits = 0;

	for (; *s != '\0'; s++) {
		if (*s >= '0' && *s <= '9') {
			cur = cur * 10 + (*s - '0');
			digits++;
		} else if (*s == ':' && digits > 0) {
			total = total * 60 + cur;
			cur = 0;
			digits = 0;
		} else {
			return 0;
		}
	}

	return digits > 0 ? total * 60 + cur : 0;
}

int bili_cover_url(const char *pic, int w, int h, char *out, size_t size)
{
	const char *p = pic;
	int n;

	if (strncmp(p, "https://", 8) == 0) {
		p += 8;
	} else if (strncmp(p, "http://", 7) == 0) {
		p += 7;
	} else if (strncmp(p, "//", 2) == 0) {
		p += 2;
	} else {
		return -EINVAL;
	}
	if (strchr(p, '@') != NULL) {
		n = snprintf(out, size, "http://%s", p);
	} else {
		n = snprintf(out, size, "http://%s@%dw_%dh_1c.jpg", p, w, h);
	}

	return n >= (int)size ? -ENOSPC : n;
}

int bili_parse_playurl(const char *json, struct bili_stream *out)
{
	const char *d = js_first(js_path(json, "data.durl"));

	if (d == NULL || js_str(js_get(d, "url"), out->url, sizeof(out->url)) <= 0) {
		return -ENOENT;
	}
	out->size = js_int(js_get(d, "size"), 0);
	out->length_ms = js_int(js_get(d, "length"), 0);
	out->quality = js_int(js_path(json, "data.quality"), 0);

	return 0;
}
```

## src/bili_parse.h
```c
/*
 * Copyright (c) 2026 Yuzuki Tsuru
 *
 * SPDX-License-Identifier: Apache-2.0
 */

/* What the answers of the web API are made into; no I/O here */

#ifndef BILI_PARSE_H_
#define BILI_PARSE_H_

#include <stddef.h>
#include <stdint.h>

struct bili_video {
	char bvid[16];
	char title[160];
	char author[40];
	char cover[160];
	uint64_t cid;		/**< 0 for a search result: bili_parse_view_cid() asks for it */
	uint32_t duration;	/**< seconds */
	uint32_t views;
	uint32_t danmaku;
};

#define BILI_HOT_WORD_LEN	40

struct bili_stream {
	char url[512];
	uint64_t size;		/**< bytes of the file */
	uint32_t length_ms;
	int quality;		/**< 16 is 360P, 32 480P, 64 720P */
	uint64_t cid;		/**< of the video (a search result gets it looked up), set by bili_api_stream() */
};

/**
 * Checks the envelope of an answer: 0 when "code" is 0, else the (positive) code of the server
 * or -EBADMSG when there is none.
 */
int bili_parse_code(const char *json);

/** The WBI key from the nav answer (which also comes as code -101 without a login) */
int bili_parse_nav(const char *json, char key[33]);

/** The videos of the recommendation feed; entries that are no plain video (ads, live) are skipped */
int bili_parse_feed(const char *json, struct bili_video *out, int max);

/** The popular list (/x/web-interface/popular); same result as bili_parse_feed() */
int bili_parse_popular(const char *json, struct bili_video *out, int max);

/**
 * The results of a video search. The marks around the found words are removed from the titles.
 * @p pages gets the number of result pages (may be NULL). Returns the number of videos.
 */
int bili_parse_search(const char *json, struct bili_video *out, int max, int *pages);

/** The trending search words; returns how many were copied into @p words */
int bili_parse_hot_words(const char *json, char words[][BILI_HOT_WORD_LEN], int max);

/**
 * The cid of the first part of a video from /x/player/pagelist (data is an array). The answer of
 * /x/web-interface/view also works, but it can be 150 KB for a video of a large series.
 */
int bili_parse_view_cid(const char *json, uint64_t *cid);

/** Removes <tags> from @p s in place and decodes the common HTML entities */
void bili_strip_html(char *s);
/** Full width Latin letters, digits and punctuation become the ordinary ones (in place) */
void bili_fold_width(char *s);

/** "75", "2:05", "1:02:03" (fields without leading zeros are fine) to seconds, 0 when not a time */
uint32_t bili_parse_clock(const char *s);

/**
 * The address of a cover scaled by the image server to @p w x @p h (cropped), as an http URL;
 * a protocol-less or https address is turned into http. Returns the length or a negative errno.
 */
int bili_cover_url(const char *pic, int w, int h, char *out, size_t size);

/** The first file of a playurl answer */
int bili_parse_playurl(const char *json, struct bili_stream *out);

#endif /* BILI_PARSE_H_ */
```

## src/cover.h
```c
/*
 * Copyright (c) 2026 Yuzuki Tsuru
 *
 * SPDX-License-Identifier: Apache-2.0
 */

/*
 * The cover pictures of the lists. A thread fetches the small JPEG of the image server, decodes it
 * with the video engine and keeps the RGB565 result in a cache. The user interface asks for a
 * cover by its address, uses the pixels while it holds a reference and gives it back; only covers
 * without a reference are thrown out when the cache is full.
 */

#ifndef BILI_COVER_H_
#define BILI_COVER_H_

#include <stdbool.h>
#include <stdint.h>

#define COVER_W	236
#define COVER_H	133

/*
 * The pixels of a cover are RGB565 with this many bytes from one row to the next, and the memory is
 * aligned to 64 bytes: the image drawing of LVGL needs both (a row of 472 bytes gave noise).
 */
#define COVER_STRIDE	512
#define COVER_BYTES	(COVER_STRIDE * COVER_H)

void cover_init(void);

/** Queues a fetch of the cover with the address @p pic (as in struct bili_video) unless it is known */
void cover_request(const char *pic);

/**
 * The pixels (COVER_H rows of COVER_STRIDE bytes, RGB565) when the cover is ready, with a reference taken, else NULL.
 * Every non NULL result has to be given back with cover_release().
 */
const uint16_t *cover_acquire(const char *pic);
void cover_release(const char *pic);

/** Increases whenever a cover became ready or failed: the user interface looks again */
uint32_t cover_version(void);

/** No fetches while the video engine belongs to the player */
void cover_pause(bool pause);

/** How many covers the user interface still holds */
int cover_in_use(void);

/** Throws out every cover without a reference and forgets the queued requests */
void cover_flush(void);

/** The pixels of the n-th ready cover, no reference taken: for tests only */
const uint16_t *cover_peek(int n);

/** Covers that are asked for and not there yet */
int cover_pending(void);
void cover_stats(char *buf, unsigned int size);

#endif /* BILI_COVER_H_ */
```

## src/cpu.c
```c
/*
 * Copyright (c) 2026 Yuzuki Tsuru
 *
 * SPDX-License-Identifier: Apache-2.0
 */

/* Raises the CPU clock above what the boot stub sets up (600 MHz) */

#include <stdlib.h>
#include <zephyr/device.h>
#include <zephyr/drivers/clock_control.h>
#include <zephyr/dt-bindings/clock/sun252i-f101-ccu.h>
#include <zephyr/kernel.h>
#include <zephyr/sys/printk.h>


/* A busy loop over a checksummed block of memory: a CPU that is too fast corrupts it */
static bool cpu_selftest(void)
{
	/* from the malloc arena, so that no RAM stays reserved after the start */
	const unsigned int words = 16 * 1024;
	uint32_t *blk = malloc(words * sizeof(*blk));
	uint32_t sum = 0, ref = 0;
	bool ok = true;

	if (blk == NULL) {
		return true;
	}
	for (unsigned int i = 0; i < words; i++) {
		blk[i] = i * 2654435761U;
	}
	for (int round = 0; ok && round < 50; round++) {
		sum = 0;
		for (unsigned int i = 0; i < words; i++) {
			sum = (sum << 1 | sum >> 31) ^ blk[i] ^ (sum * 3U);
		}
		if (round == 0) {
			ref = sum;
		} else if (sum != ref) {
			ok = false;
		}
	}
	free(blk);

	return ok;
}

void cpu_clock_setup(void)
{
	const struct device *cctl = DEVICE_DT_GET(DT_NODELABEL(cctl));
	uint32_t rate, target = CONFIG_BILI_CPU_MHZ * 1000000U;

	clock_control_get_rate(cctl, (clock_control_subsys_t)CLK_CPU, &rate);
	/* in steps, each one checked: the voltage is not changed */
	while (target != 0U && rate < target) {
		uint32_t next = MIN(rate + 72000000U, target);

		if (clock_control_set_rate(cctl, (clock_control_subsys_t)CLK_CPU,
					   (clock_control_subsys_rate_t)next) != 0) {
			printk("cpu: %u MHz refused\n", next / 1000000U);
			break;
		}
		if (!cpu_selftest()) {
			printk("cpu: %u MHz BAD\n", next / 1000000U);
			clock_control_set_rate(cctl, (clock_control_subsys_t)CLK_CPU,
					       (clock_control_subsys_rate_t)rate);
			printk("cpu: back to %u MHz\n", rate / 1000000U);
			return;
		}
		rate = next;
	}
	printk("cpu: %u MHz\n", rate / 1000000U);
}
```

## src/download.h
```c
/*
 * Copyright (c) 2026 Yuzuki Tsuru
 *
 * SPDX-License-Identifier: Apache-2.0
 */

#ifndef BILI_DOWNLOAD_H_
#define BILI_DOWNLOAD_H_

#include <stdint.h>

/** Called as the file grows; a non zero return aborts the download */
typedef int (*dl_progress_fn)(uint64_t done, uint64_t total, void *ctx);

/**
 * Downloads @p url into the file @p path (replaced), continuing with a Range request after a
 * broken connection. @p total is the expected size, 0 if unknown. Returns 0 when the file is
 * complete, a negative errno otherwise (-ECANCELED after an abort; the partial file is removed).
 */
int dl_file(const char *url, const char *path, uint64_t total, dl_progress_fn fn, void *ctx);

/**
 * The same download in a thread of its own, for a file that is played while it arrives. The file exists
 * and is synced after every 64 KiB; dl_avail() (a player_growing callback) tells how much of it a
 * reader may use: *state is 0 while it runs, 1 when it is complete, negative on failure or after
 * dl_stop(). The partial file of a failed or stopped download stays for the caller to remove (a reader may still have it open). One at a time.
 */
int dl_start(const char *url, const char *path, uint64_t total, dl_progress_fn fn, void *ctx);
uint64_t dl_avail(void *ctx, int *state);
/** HTTP status of the last answer of a download (0 after a connection error), for messages */
int dl_last_status(void);
/** Stops the download and waits for its thread */
void dl_stop(void);

#endif /* BILI_DOWNLOAD_H_ */
```

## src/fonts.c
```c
/*
 * Copyright (c) 2026 Yuzuki Tsuru
 *
 * SPDX-License-Identifier: Apache-2.0
 */

/*
 * The text font: Noto Sans SC (SIL OFL), cut down to the GB2312 characters, the kana and the
 * punctuation by tools/make_font.py and linked into the firmware. TinyTTF draws the glyphs from it
 * on demand; the font data itself is read in place.
 */

#include <lvgl.h>
#include <zephyr/sys/printk.h>

#include "ui_priv.h"

/* glyphs kept per font size: the bitmaps of a screen full of titles */
#define GLYPH_CACHE	384

static const uint8_t ttf[] = {
#include "font.inc"
};

const lv_font_t *ui_font_s, *ui_font_m, *ui_font_l;

static const lv_font_t *make(int px)
{
	lv_font_t *f = lv_tiny_ttf_create_data_ex(ttf, sizeof(ttf), px, LV_FONT_KERNING_NONE,
						  GLYPH_CACHE);

	if (f == NULL) {
		printk("ui: the font %d px could not be made\n", px);
		return &lv_font_montserrat_20;
	}
	/* the symbols of LVGL (arrows, play, ...) are not in the font */
	f->fallback = &lv_font_montserrat_20;

	return f;
}

void ui_fonts_init(void)
{
	ui_font_s = make(18);
	ui_font_m = make(22);
	ui_font_l = make(28);
	printk("ui: font of %u KiB\n", (unsigned int)(sizeof(ttf) >> 10));
}
```
